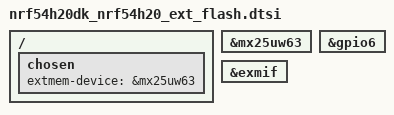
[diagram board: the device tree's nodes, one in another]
/*
 * Copyright (c) 2025 Nordic Semiconductor ASA
 *
 * SPDX-License-Identifier: LicenseRef-Nordic-5-Clause
 */

#include "nrf54h20dk_nrf54h20_memory_map_ext_flash.dtsi"

/ {
	chosen {
		extmem-device = &mx25uw63;
	};
};

&mx25uw63 {
	status = "okay";
};

&gpio6 {
	status = "okay";
};

&exmif {
	status = "okay";
};
